# SF32LB57x register map
File version: 1.0
CPU: CM33 r0p1, little endian, MPU, FPU, 3 interrupt priority bits
Registers are 32-bit, read-write, reset 0x0 unless marked. A register's access mark holds for its fields unless they carry their own. Offsets are from the block's base; [hi:lo] are bit positions; {n}, {i} and the like mark numbered series.

## I2S1
Base 0x50009000
Same registers: I2S2 0x5008A000
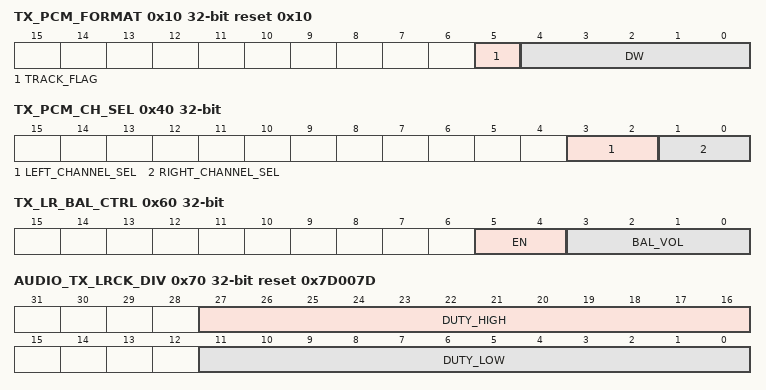
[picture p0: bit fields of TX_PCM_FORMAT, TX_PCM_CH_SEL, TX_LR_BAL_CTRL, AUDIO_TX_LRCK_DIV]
0x10 TX_PCM_FORMAT reset 0x10
  [5] TRACK_FLAG — 0: stereo 1: mono
  [4:0] DW — tx source pcm data width N(N>=8) common value is 8,13,14,16,18,20,22,24 This data width indicate the tx fifo output data width. When writing to tx fifo, please refer to following format: ※Mono 8 bit: fifo_data[31:0] = {L3,L2,L1,L0}, each word contains 4 samples, so four samples need read one word ※Stereo 8 bit: fifo_data[31:0] = { R1,L1,R0,L0 }, each word contains 2 samples, so two samples need read one word ※Mono 13/14/16 bit: fifo_data[31:0] = {L1,L0}, each word contains 2 samples, so two samples need read one word ※Stereo 13/14/16 bit: fifo_data[31:0] = {R0,L0}, each word contains 1 samples, so each sample need read one word ※Mono 18/20/22/24 bit: fifo_data[31:0] = L0, each word contains 1 samples, so each sample need read one word ※Stereo 18/20/22/24 bit: fifo_data[31:0][0] = {L0}, fifo_data[31:0][1]={R0}, each 2 words contain 1 samples, so each sample need read two word
0x20 TX_PCM_SAMPLE_CLK reset 0xFA
  [12:0] FS_DUTY — source PCM sample clock duty cycle(with GCLK=12MHz): 250 for 48K FS 272 for 44.1K FS 375 for 32K FS 500 for 24K FS 544 for 22.05K FS 750 for 16K FS 1000 for 12K FS 1088 for 11.025K FS 1500 for 8K FS
0x30 TX_RS_SMOOTH
  [0] EN — 0: Disable TX re-sample smooth filter 1: Enable TX re-sample smooth filter This function is not implemented.
0x40 TX_PCM_CH_SEL
  [3:2] LEFT_CHANNEL_SEL — TX re-sampling module setting: 00: TX left = source left 01: TX left = source right 10,11: TX left = (source left + source right)/2
  [1:0] RIGHT_CHANNEL_SEL — TX re-sampling module setting: 00: TX right = source right 01: TX right = source left 10,11: TX right = (source left + source right)/2
0x50 TX_VOL_CTRL reset 0xF
  [3:0] VOL — volume control: 0000: +6dB, 0001: +4.5dB, 0010: +3dB, 0011: +1.5dB, 0100: 0dB, 0101: -1.5dB, 0110: -3.0dB, 0111: -4.5dB, 1000: -6.0dB, 1001: -7.5dB, 1010: -9dB, 1011: -10.5dB, 1100: -12dB, 1101: -13.5dB, 1110: -15dB, 1111: mute Note: 1) +1.5db = 20log(1+1/4-1/16+1/1024) 2) -1.5dB = 20log(1-1/8-1/32-1/512-1/2048)
0x60 TX_LR_BAL_CTRL
  [5:4] EN — LR balance enable: 00: both left and right in full volume 10: left channel balance volume adjustment enable 01: right channel balance volume adjustment enable 11: reserved, still kepp left and right in full volume
  [3:0] BAL_VOL — Balance volume control: 0000: Reserved, 0001: -1.5dB, 0010: -3.0dB, 0011: -4.5dB, 0100: -6.0dB, 0101: -7.5dB, 0110: -9.0dB, 0111: -10.5dB, 1000: -12dB, 1001: -13.5dB, 1010: -15dB, 1011: -16.5dB, 1100: -18dB, 1101: -19.5dB, 1110: -21dB, 1111: mute Note: 1) bit[5:0] = 101111 for left mute 2) bit[5:0] = 011111 for right mute 3) bit[5:4] = 00 or 11, bit[3:0] is don't care 4) +1.5db = 20log(1+1/4-1/16+1/1024) 5) -1.5dB = 20log(1-1/8-1/32-1/512-1/2048)
0x70 AUDIO_TX_LRCK_DIV reset 0x7D007D
  [27:16] DUTY_HIGH — TX LRCK duty cycle high: 125 for 48K FS 136 for 44.1K FS 185 for 32K FS 250 for 24K FS 272 for 22.05K FS 375 for 16K FS 500 for 12K FS 544 for 11.025K FS 750 for 8K FS
  [11:0] DUTY_LOW — TX LRCK duty cycle low: 125 for 48K FS 136 for 44.1K FS 190 for 32K FS 250 for 24K FS 272 for 22.05K FS 375 for 16K FS 500 for 12K FS 544 for 11.025K FS 750 for 8K FS Note: 1)duty_cycle = 12M/FS
0x80 AUDIO_TX_BCLK_DIV
  [5:0] DUTY — TX serial bit clock duty cycle 5 for 48K FS 4 for 44.1K FS 5 for 32KFS 10 for 24K FS 8 for 22.05K FS 15 for 16K FS 20 for 12K FS 16 for 11.025K FS 30 for 8KFs
0x90 AUDIO_TX_FORMAT
  [4:0] PCM_DATA_WIDTH — I2S out pcm data width M >= 16, common value: 16, 18, 20, 22, 24
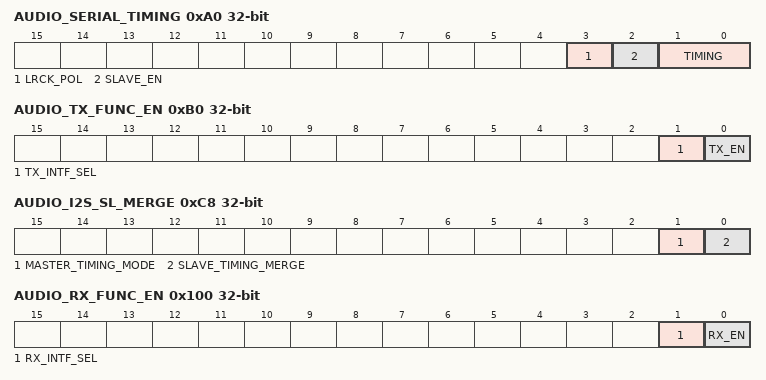
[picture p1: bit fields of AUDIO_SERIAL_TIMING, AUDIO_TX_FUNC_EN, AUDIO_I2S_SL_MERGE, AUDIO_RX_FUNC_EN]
0xA0 AUDIO_SERIAL_TIMING
  [3] LRCK_POL — TX LRCK polarity control. 0: disable TX_LRCK inventor 1: enable TX_LRCK inventor for standard I2S, set tx_lrck_pol to low for Left/Right Justified, set tx_lrck_pol to hgih
  [2] SLAVE_EN — audio code transmit mode select. 0: master mode, 1: slave mode
  [1:0] TIMING — 00: I2S mode 01: Left justified 10: right justified 11: reserved
0xB0 AUDIO_TX_FUNC_EN
  [1] TX_INTF_SEL — 1: select external tx interface 0: select internal apb tx interface
  [0] TX_EN — 1: enable 0:disable
0xC0 AUDIO_TX_PAUSE
  [0] TX_PAUSE — TX pause control when tx_enable = 1. 1: pause 0: TX work
0xC8 AUDIO_I2S_SL_MERGE
  [1] MASTER_TIMING_MODE — when work as an I2S master, and external I2S master TX/RX share one BCLK/LRCK, this bit should be set high. In this situation, TX should be set as master and RX should be set as slave. 0: when TX set as master and RX set as slave, RX clock is directly from TX. 1: when TX set as master and RX set as slave, RX clock is still from external pin.
  [0] SLAVE_TIMING_MERGE — when work as an I2S slave, and external I2S master TX/RX share one BCLK/LRCK, this bit should be set high. 0: I2S slave use separated timing control port. TX_BCLK_IN/TX_LRCK_IN and RX_BCLK/RX_LRCK_IN are separated. 1: I2S slave use the same BCLK/LRCK, the TX_BCLK_IN/TX_LRCK also is used for RX controller.
0x100 AUDIO_RX_FUNC_EN
  [1] RX_INTF_SEL — 1: select external rx interface 0: select internal apb rx interface
  [0] RX_EN — 1: enable 0: disable
0x110 AUDIO_RX_PAUSE
  [0] RX_PAUSE — RX pause control when rx_enable = 1. 1: pause 0: RX work
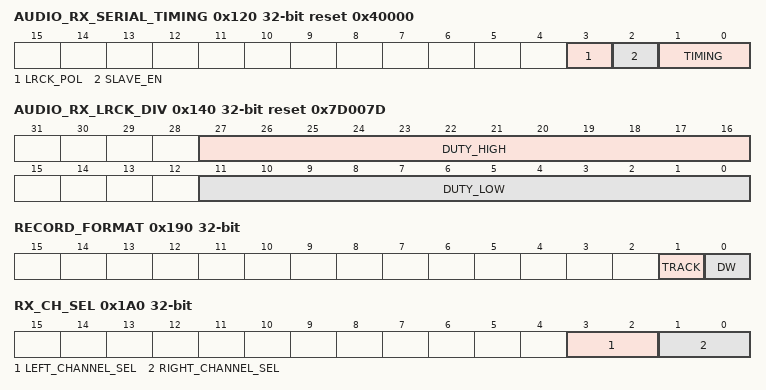
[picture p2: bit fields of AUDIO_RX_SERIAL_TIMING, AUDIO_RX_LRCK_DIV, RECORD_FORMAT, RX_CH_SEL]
0x120 AUDIO_RX_SERIAL_TIMING reset 0x40000
  [3] LRCK_POL — RX LRCK polarity control. 0: disable RX_LRCK inventor 1: enable RX_LRCK inventor for standard I2S, set tx_lrck_pol to low for Left/Right Justified, set tx_lrck_pol to hgih
  [2] SLAVE_EN — audio code receiver mode select. 0: master mode, 1: slave mode
  [1:0] TIMING — 00: I2S 01: Left justified 10: right justified 11: reserved
0x130 AUDIO_RX_PCM_DW reset 0x10
  [4:0] PCM_DATA_WIDTH — For I2S and left justified mode, M can be 8,13,14,16 For right justified mode, M can be 8, 13, 14, 16, 18, 20, 22, 24
0x140 AUDIO_RX_LRCK_DIV reset 0x7D007D
  [27:16] DUTY_HIGH — RX LRCK duty cycle high: 125 for 48K FS 136 for 44.1K FS 185 for 32K FS 250 for 24K FS 272 for 22.05K FS 375 for 16K FS 500 for 12K FS 544 for 11.025K FS 750 for 8K FS
  [11:0] DUTY_LOW — RX LRCK duty cycle low: 125 for 48K FS 136 for 44.1K FS 190 for 32K FS 250 for 24K FS 272 for 22.05K FS 375 for 16K FS 500 for 12K FS 544 for 11.025K FS 750 for 8K FS Note: 1)duty_cycle = 12M/FS
0x150 AUDIO_RX_BCLK_DIV reset 0x5
  [9:0] DUTY — RX serial bit clock duty cycle 5 for 48K FS 4 for 44.1K FS 5 for 32KFS 10 for 24K FS 8 for 22.05K FS 15 for 16K FS 20 for 12K FS 16 for 11.025K FS 30 for 8KFs
0x160 RECORD_DATA_SEL
  [0] RS_DATA_SEL — 0: I2S audio recording 1: BT recording
0x170 RX_RE_SAMPLE_CLK_DIV reset 0x7D
  [12:0] RS_DUTY — source PCM sample clock duty cycle: 250 for 48K FS 272 for 44.1K FS 375 for 32K FS 500 for 24K FS 544 for 22.05K FS 750 for 16K FS 1000 for 12K FS 1088 for 11.025K FS 1500 for 8K FS Note: 1)duty_cycle = 12M/FS
0x180 RX_RE_SAMPLE
  [0] SMOOTH_EN — 0: Disable RX re-sample smooth filter 1: Enable RX re-sample smooth filter
0x190 RECORD_FORMAT
  [1] TRACK — 1: mono recording, 0: stereo recording
  [0] DW — 0: 8bit 1: 16bit RX fifo data format: ※Mono 8 bit (unsigned): RX FIFO_DIN[31:0] = {L3,L2,L1,L0}, each four samples need one FIFO write operation ※Stereo 8 bit (unsigned): RX_FIFO_DIN[31:0] = {R1,L1,R0,L0}, each tow samples need one FIFO write operation ※Mono 16 bit (Signed 2’s complement): RX_FIFO_DIN[31:0] = {L1,L0}, each two samples need one FIFO write operation ※Stereo 16 bit (Signed 2’s complement): RX_FIFO_DIN[31:0] = {R0,L0}, each sample need one FIFO write operation
0x1A0 RX_CH_SEL
  [3:2] LEFT_CHANNEL_SEL — RX re-sampling module setting: 00: RD left = RX left 01: RD left = RX right 10,11: RD left = (RX left + RX right)/2
  [1:0] RIGHT_CHANNEL_SEL — RX re-sampling module setting: 00: RD right = RX right 01: RD right = RX left 10,11: RD right = (RX left + RX right)/2
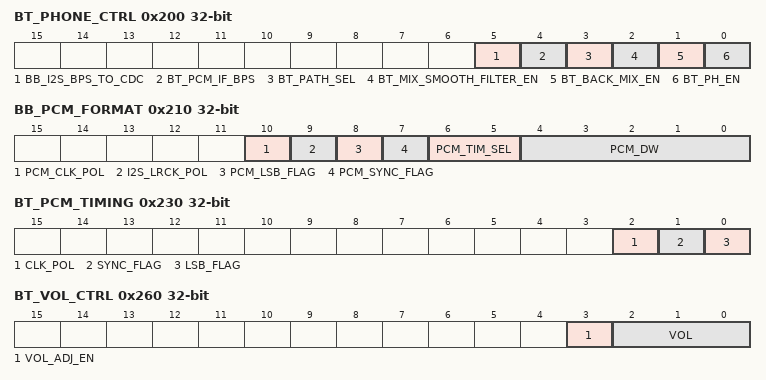
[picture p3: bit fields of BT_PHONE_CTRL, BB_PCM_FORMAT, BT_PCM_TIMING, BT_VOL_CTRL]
0x200 BT_PHONE_CTRL
  [5] BB_I2S_BPS_TO_CDC — bypass baseband I2S interface to audio codec i2s interface 0: no bypass, 1: bypass
  [4] BT_PCM_IF_BPS — bypass baseband PCM signals to BT VCI master: 0: no bypass, 1: bypass
  [3] BT_PATH_SEL — BT path select 0: digital path, 1: analog path
  [2] BT_MIX_SMOOTH_FILTER_EN — 0: disable the smooth filter for background mixer 1: enable the smooth filer for background mixer
  [1] BT_BACK_MIX_EN — background mixer enable 0: disable, 1: enable
  [0] BT_PH_EN — BT phone enable 0: disable, 1: enable
0x210 BB_PCM_FORMAT
  [10] PCM_CLK_POL — input BB pcm clock polarity: 0: rising edge for data transmitting, falling edge for data receiving 1: rising edge for data receiving, falling edge for data transmitting
  [9] I2S_LRCK_POL — 0: no bb_i2s_lrck input inventor 1: enable bb_i2s_lrck input inventor for standard I2S, set tx_lrck_pol to low for Left/Right Justified, set tx_lrck_pol to high
  [8] PCM_LSB_FLAG — Serial PCM data bit sequence. 0: MSB first, 1: LSB first
  [7] PCM_SYNC_FLAG — 0: short sync, 1: long sync
  [6:5] PCM_TIM_SEL — 00: I2S timing, 01: Left Justified 10: Right Justified, 11: PCM timing
  [4:0] PCM_DW — Baseband Master PCM data width (>=8) Common value: 8, 13,14, 16, 18, 20, 22, 24. for I2S/Left Justified/Right Kistified timing, bb_pcm_dw >=16 For PCM timing, only 8, 13, 14, 16 configure value is available.
0x220 BT_PCM_DW reset 0x10
  [4:0] DW — BT PCM master data width (>= 8), common value: 8, 13,14, 16
0x230 BT_PCM_TIMING
  [2] CLK_POL — BT PCM master output pcm clock polarity: 0: rising edge for data transmitting, falling edge for data receiving 1: rising edge for data receiving, falling edge for data transmitting
  [1] SYNC_FLAG — 0: short sync, 1: long sync
  [0] LSB_FLAG — Serial PCM data bit sequence. 0: MSB first, 1: LSB first
0x240 BT_PCM_CLK_DUTY
  [9:0] CLK_DUTY — BT_PCM_CLK duty cycle lte (GCLK/(bt_pcm_sync*bt_pcm_dw))
0x250 BT_PCM_SYNC_DUTY
  [5:0] SYNC_DUTY — PCM_SYNC duty cycle (bt_pcm_sync frequency = bt_pclk_clk/bt_pcm_sync_duty)
0x260 BT_VOL_CTRL
  [3] VOL_ADJ_EN — BT volume adjust enable
  [2:0] VOL — BT master volume
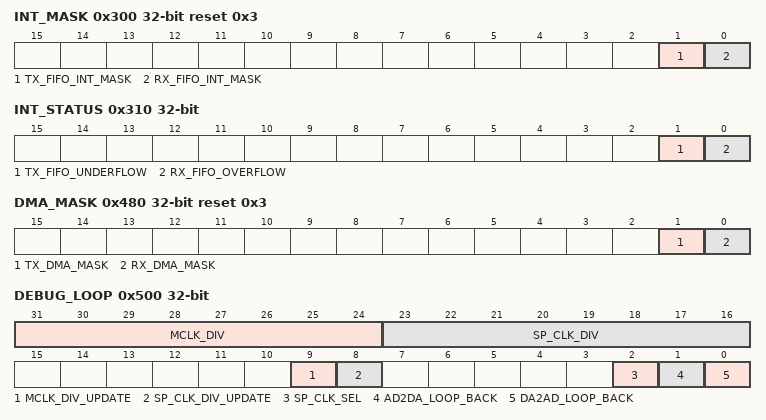
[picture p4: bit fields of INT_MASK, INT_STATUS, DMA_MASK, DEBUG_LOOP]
0x300 INT_MASK reset 0x3
  [1] TX_FIFO_INT_MASK — Interrupt mask for TX FIFO pop underflow, high active
  [0] RX_FIFO_INT_MASK — Interrupt mask for RX FIFO push overflow, high active
0x310 INT_STATUS
  [1] TX_FIFO_UNDERFLOW — TX FIFO pop underflow
  [0] RX_FIFO_OVERFLOW — RX FIFO push overflow
0x400 TX_DMA_ENTRY
0x440 RX_DMA_ENTRY
0x480 DMA_MASK reset 0x3
  [1] TX_DMA_MASK — TX DMA mask enable:1: mask0: do not mask
  [0] RX_DMA_MASK — RX DMA mask enable:1: mask0: do not mask
0x500 DEBUG_LOOP
  [31:24] MCLK_DIV — mclk divider value
  [23:16] SP_CLK_DIV — sp clock divider value
  [9] MCLK_DIV_UPDATE — update mclk divider
  [8] SP_CLK_DIV_UPDATE — update sp clock divider
  [2] SP_CLK_SEL — clock select 0: xtal clock 1: pll clock
  [1] AD2DA_LOOP_BACK — RX-->TX Loop debug control: 0: disable 1: enable, internally connect RX Resampled PCM to TX Resample PCM input
  [0] DA2AD_LOOP_BACK — TX-->RX Loop debug control: 0: disable 1: enable, internally connect TX SDTO to RX SDTI
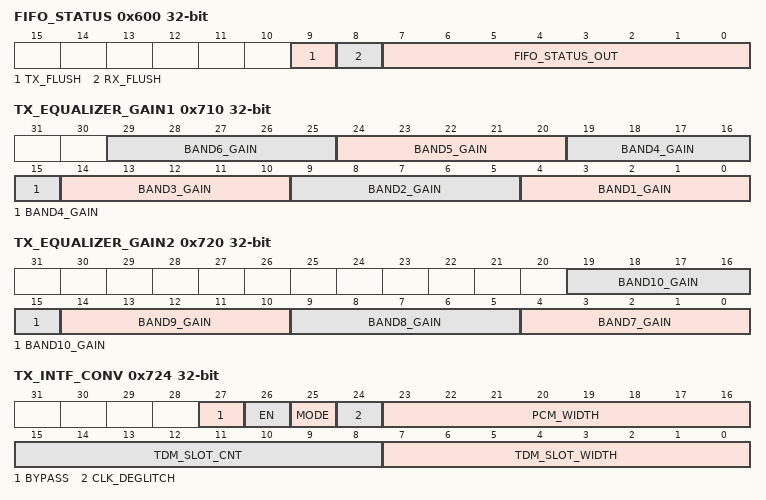
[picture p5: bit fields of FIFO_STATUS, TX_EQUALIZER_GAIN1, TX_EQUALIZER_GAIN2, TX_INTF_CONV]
0x600 FIFO_STATUS
  [9] TX_FLUSH — 1: flush tx fifo
  [8] RX_FLUSH — 1: flush rx fifo
  [7:0] FIFO_STATUS_OUT — FIFO Status output: Bit [7:0] = {tx_full,tx_empty,tx_almost_full,tx_almost_empty,rx_full,rx_empty,rx_almost_full,rx_almost_empty}
0x700 TX_EQUALIZER_EN
  [0] TX_EQUALIZER_EN — 0: Disable TX equalizer 1: Enable TX equalizer equalizer is not implemented
0x710 TX_EQUALIZER_GAIN1
  [5n-1:5n-5] BAND{n}_GAIN (n=1..6)
0x720 TX_EQUALIZER_GAIN2
  [5n-31:5n-35] BAND{n}_GAIN (n=7..10)
0x724 TX_INTF_CONV
  [27] BYPASS — 1: bypass tx_intf_conv module
  [26] EN — 1: enable tx_intf_conv module
  [25] MODE — 0: i2s 1: pcm
  [24] CLK_DEGLITCH — 1: use gclk for bclk de-glitching
  [23:16] PCM_WIDTH — pcm fsync signal width
  [15:8] TDM_SLOT_CNT — TDM mode slot number
  [7:0] TDM_SLOT_WIDTH — TDM mode slot width
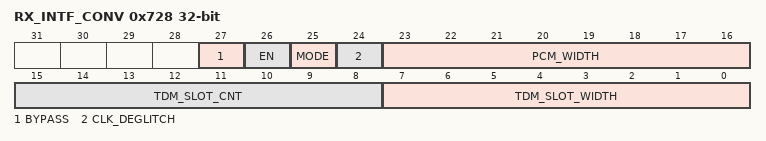
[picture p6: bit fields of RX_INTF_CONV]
0x728 RX_INTF_CONV
  [27] BYPASS — 1: bypass rx_intf_conv module
  [26] EN — 1: enable rx_intf_conv module
  [25] MODE — 0: i2s 1: pcm
  [24] CLK_DEGLITCH — 1: use gclk for bclk de-glitching
  [23:16] PCM_WIDTH — pcm fsync signal width
  [15:8] TDM_SLOT_CNT — TDM mode slot number
  [7:0] TDM_SLOT_WIDTH — TDM mode slot width
